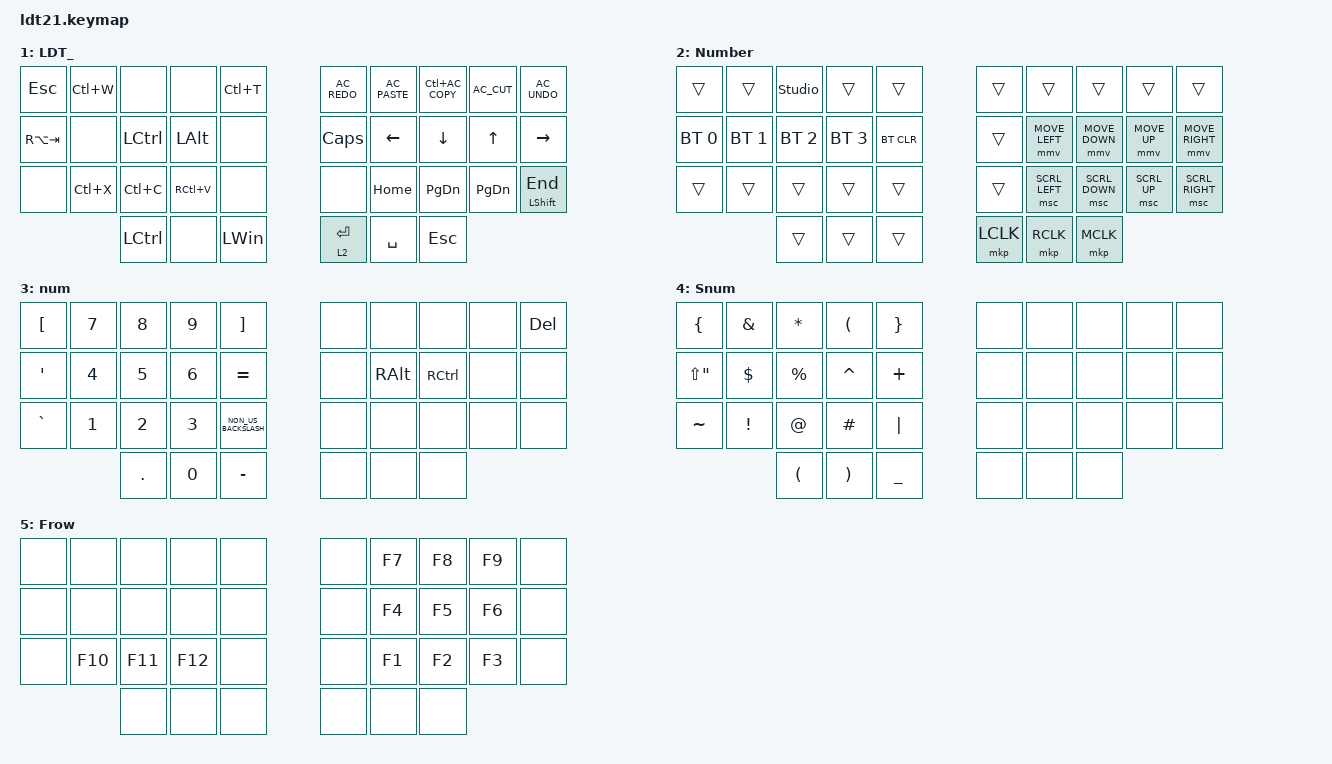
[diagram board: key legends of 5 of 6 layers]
/*
 * Copyright (c) 2020 The ZMK Contributors
 * LDT
 * SPDX-License-Identifier: MIT
 */




#define DEF 0
#define NAV 1
#define NUM 2


#include <dt-bindings/zmk/bt.h>
#include <dt-bindings/zmk/keys.h>
#include <dt-bindings/zmk/pointing.h>

/ {
    combos {
        compatible = "zmk,combos";

        // Thumb combos
        // Brackets - Ngoặc vuông []
        // Braces - Ngoặc nhọn {}
        // Parentheses - Ngoặc tròn ()
        // Special chars
        // Word navigation - Windows (Layer 0)
        // Word navigation - Mac (Layer 1)
        // Arrow keys

        copy {
            bindings = <&kp LC(C)>;
            key-positions = <12 13>;
            slow-release;
            require-prior-idle-ms = <150>;
            timeout-ms = <280>;
            layers = <0>;
        };

        ctrl {
            bindings = <&kp LCTRL>;
            key-positions = <10 12>;
        };
    };

    keymap {
        compatible = "zmk,keymap";

        ldt21_layer {
            bindings = <
&kp Q             &kp W  &kp E                &kp R            &kp T      &kp Y        &kp U      &kp I            &kp O    &kp P
&kp A      &kp S      &kp D       &kp F     &kp K            &kp L    &mt RCTRL SEMICOLON
&mt LEFT_SHIFT Z  &kp X  &kp C                &kp V            &kp B      &kp N        &kp M      &kp COMMA        &kp DOT  &mt LEFT_SHIFT SLASH
                         &mt LEFT_GUI ESCAPE  &lt 1 BACKSPACE  &lt 2 TAB  &lt 4 ENTER  &kp SPACE  &lt 3 RIGHT_GUI
            >;

            label = "LDT";
        };

        nav {
            label = "LDT_";
            bindings = <
&kp ESCAPE   &kp LC(W)  &none      &none         &kp LC(T)     &kp C_AC_REDO  &kp C_AC_PASTE  &kp LC(C_AC_COPY)  &kp C_AC_CUT  &kp C_AC_UNDO
&kp RA(TAB)  &none      &kp LCTRL  &kp LEFT_ALT  &none         &kp CAPS       &kp LEFT_ARROW  &kp DOWN           &kp UP_ARROW  &kp RIGHT
&none        &kp LC(X)  &kp LC(C)  &kp RC(V)     &none         &none          &kp HOME        &kp PAGE_DOWN      &kp PG_DN     &mt LEFT_SHIFT END
                        &kp LCTRL  &none         &kp LEFT_WIN  &lt 2 ENTER    &kp SPACE       &kp ESCAPE
            >;
        };

        mouse {
            bindings = <
&trans        &trans        &studio_unlock  &trans        &trans      &trans     &trans          &trans          &trans        &trans
&bt BT_SEL 0  &bt BT_SEL 1  &bt BT_SEL 2    &bt BT_SEL 3  &bt BT_CLR  &trans     &mmv MOVE_LEFT  &mmv MOVE_DOWN  &mmv MOVE_UP  &mmv MOVE_RIGHT
&trans        &trans        &trans          &trans        &trans      &trans     &msc SCRL_LEFT  &msc SCRL_DOWN  &msc SCRL_UP  &msc SCRL_RIGHT
                            &trans          &trans        &trans      &mkp LCLK  &mkp RCLK       &mkp MCLK
            >;

            label = "Number";
        };

        num {
            bindings = <
&kp LEFT_BRACKET  &kp NUMBER_7  &kp NUMBER_8  &kp NUMBER_9  &kp RIGHT_BRACKET     &none  &none          &none      &none  &kp DEL
&kp SINGLE_QUOTE  &kp NUMBER_4  &kp NUMBER_5  &kp NUMBER_6  &kp EQUAL             &none  &kp RIGHT_ALT  &kp RCTRL  &none  &none
&kp GRAVE         &kp NUMBER_1  &kp NUMBER_2  &kp NUMBER_3  &kp NON_US_BACKSLASH  &none  &none          &none      &none  &none
                                &kp PERIOD    &kp N0        &kp MINUS             &none  &none          &none
            >;
        };

        Snum {
            bindings = <
&kp LEFT_BRACE         &kp AMPERSAND    &kp ASTERISK          &kp LPAR               &kp RIGHT_BRACE  &none  &none  &none  &none  &none
&kp LS(DOUBLE_QUOTES)  &kp DOLLAR       &kp PERCENT           &kp CARET              &kp PLUS         &none  &none  &none  &none  &none
&kp TILDE              &kp EXCLAMATION  &kp AT_SIGN           &kp HASH               &kp PIPE         &none  &none  &none  &none  &none
                                        &kp LEFT_PARENTHESIS  &kp RIGHT_PARENTHESIS  &kp UNDERSCORE   &none  &none  &none
            >;
        };

        Frow {
            bindings = <
&none  &none    &none    &none    &none  &none  &kp F7  &kp F8  &kp F9  &none
&none  &none    &none    &none    &none  &none  &kp F4  &kp F5  &kp F6  &none
&none  &kp F10  &kp F11  &kp F12  &none  &none  &kp F1  &kp F2  &kp F3  &none
                &none    &none    &none  &none  &none   &none
            >;
        };
    };
};
